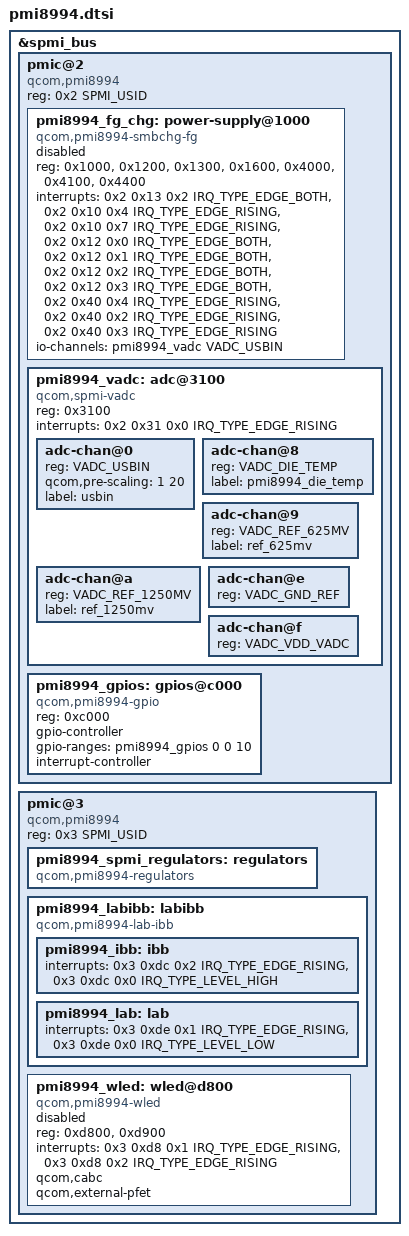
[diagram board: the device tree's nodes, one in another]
// SPDX-License-Identifier: GPL-2.0
#include <dt-bindings/iio/qcom,spmi-vadc.h>
#include <dt-bindings/interrupt-controller/irq.h>
#include <dt-bindings/spmi/spmi.h>

&spmi_bus {
	pmic@2 {
		compatible = "qcom,pmi8994", "qcom,spmi-pmic";
		reg = <0x2 SPMI_USID>;
		#address-cells = <1>;
		#size-cells = <0>;

		pmi8994_fg_chg: power-supply@1000 {
			compatible = "qcom,pmi8994-smbchg-fg";
			reg = <0x1000>, <0x1200>, <0x1300>, <0x1600>,
			      <0x4000>, <0x4100>, <0x4400>;
			reg-names = "chgr", "bat-if", "usb-chgpth", "chgr-misc",
				    "fg-soc", "fg-batt", "fg-memif";
			interrupts = <0x2 0x13 0x2 IRQ_TYPE_EDGE_BOTH>,
				     <0x2 0x10 0x4 IRQ_TYPE_EDGE_RISING>,
				     <0x2 0x10 0x7 IRQ_TYPE_EDGE_RISING>,
				     <0x2 0x12 0x0 IRQ_TYPE_EDGE_BOTH>,
				     <0x2 0x12 0x1 IRQ_TYPE_EDGE_BOTH>,
				     <0x2 0x12 0x2 IRQ_TYPE_EDGE_BOTH>,
				     <0x2 0x12 0x3 IRQ_TYPE_EDGE_BOTH>,
				     <0x2 0x40 0x4 IRQ_TYPE_EDGE_RISING>,
				     <0x2 0x40 0x2 IRQ_TYPE_EDGE_RISING>,
				     <0x2 0x40 0x3 IRQ_TYPE_EDGE_RISING>;
			interrupt-names = "usbin-src-det",
					  "chg-p2f-thr",
					  "chg-tcc-thr",
					  "batt-hot",
					  "batt-warm",
					  "batt-cold",
					  "batt-cool",
					  "delta-soc",
					  "full-soc",
					  "empty-soc";
			io-channels = <&pmi8994_vadc VADC_USBIN>;
			io-channel-names = "usbin";
			status = "disabled";
		};

		pmi8994_vadc: adc@3100 {
			compatible = "qcom,spmi-vadc";
			reg = <0x3100>;
			interrupts = <0x2 0x31 0x0 IRQ_TYPE_EDGE_RISING>;
			#address-cells = <1>;
			#size-cells = <0>;
			#io-channel-cells = <1>;

			adc-chan@0 {
				reg = <VADC_USBIN>;
				qcom,pre-scaling = <1 20>;
				label = "usbin";
			};

			adc-chan@8 {
				reg = <VADC_DIE_TEMP>;
				label = "pmi8994_die_temp";
			};

			adc-chan@9 {
				reg = <VADC_REF_625MV>;
				label = "ref_625mv";
			};

			adc-chan@a {
				reg = <VADC_REF_1250MV>;
				label = "ref_1250mv";
			};

			adc-chan@e {
				reg = <VADC_GND_REF>;
			};

			adc-chan@f {
				reg = <VADC_VDD_VADC>;
			};
		};

		pmi8994_gpios: gpios@c000 {
			compatible = "qcom,pmi8994-gpio", "qcom,spmi-gpio";
			reg = <0xc000>;
			gpio-controller;
			gpio-ranges = <&pmi8994_gpios 0 0 10>;
			#gpio-cells = <2>;
			interrupt-controller;
			#interrupt-cells = <2>;
		};
	};

	pmic@3 {
		compatible = "qcom,pmi8994", "qcom,spmi-pmic";
		reg = <0x3 SPMI_USID>;
		#address-cells = <1>;
		#size-cells = <0>;

		pmi8994_spmi_regulators: regulators {
			compatible = "qcom,pmi8994-regulators";
			#address-cells = <1>;
			#size-cells = <1>;
		};

		pmi8994_labibb: labibb {
			compatible = "qcom,pmi8994-lab-ibb";

			pmi8994_ibb: ibb {
				interrupts = <0x3 0xdc 0x2 IRQ_TYPE_EDGE_RISING>,
					     <0x3 0xdc 0x0 IRQ_TYPE_LEVEL_HIGH>;
				interrupt-names = "sc-err", "ocp";
			};

			pmi8994_lab: lab {
				interrupts = <0x3 0xde 0x1 IRQ_TYPE_EDGE_RISING>,
					     <0x3 0xde 0x0 IRQ_TYPE_LEVEL_LOW>;
				interrupt-names = "sc-err", "ocp";
			};
		};

		pmi8994_wled: wled@d800 {
			compatible = "qcom,pmi8994-wled";
			reg = <0xd800>, <0xd900>;
			interrupts = <0x3 0xd8 0x1 IRQ_TYPE_EDGE_RISING>,
				     <0x3 0xd8 0x2 IRQ_TYPE_EDGE_RISING>;
			interrupt-names = "ovp", "short";
			qcom,cabc;
			qcom,external-pfet;

			status = "disabled";
		};
	};
};
